# STM32F398xx register map
File version: 1.0
Registers are 32-bit, read-write, reset 0x0 unless marked. A register's access mark holds for its fields unless they carry their own. Offsets are from the block's base; [hi:lo] are bit positions; {n}, {i} and the like mark numbered series.

## OPAMP1 — Operational Amplifier (OPAMP)
Base 0x40010038; alternate view of OPAMP
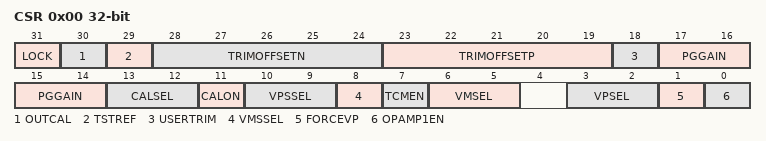
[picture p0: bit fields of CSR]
0x00 CSR — OPAMP control and status register
  [31] LOCK — OPAMP lock
  [30] OUTCAL — OPAMP output status flag
  [29] TSTREF — It enables the switch to put out the internal reference
  [28:24] TRIMOFFSETN — Offset trimming value (NMOS)
  [23:19] TRIMOFFSETP — Offset trimming value (PMOS)
  [18] USERTRIM — User trimming enable
  [17:14] PGGAIN — Gain in PGA mode
  [13:12] CALSEL — Calibration selection
  [11] CALON — Calibration mode enable
  [10:9] VPSSEL — Non inverting input secondary selection
  [8] VMSSEL — Inverting input secondary selection
  [7] TCMEN — Timer-Controlled Mux mode enable
  [6:5] VMSEL — Inverting input selection
  [3:2] VPSEL — Non inverting input selection
  [1] FORCEVP — Connect the internal references to the plus input of the OPAMPX
  [0] OPAMP1EN — OPAMP1 enable

## OPAMP2 — Operational Amplifier (OPAMP)
Base 0x4001003C
Registers as OPAMP1 (with OPAMP1 read as OPAMP2).

## OPAMP3 — Operational Amplifier (OPAMP)
Base 0x40010040
Registers as OPAMP1 (with OPAMP1 read as OPAMP3).

## OPAMP4 — Operational Amplifier (OPAMP)
Base 0x40010044
Registers as OPAMP1 (with OPAMP1 read as OPAMP4).

## EXTI — External Interrupt/Event Controller
Base 0x40010400
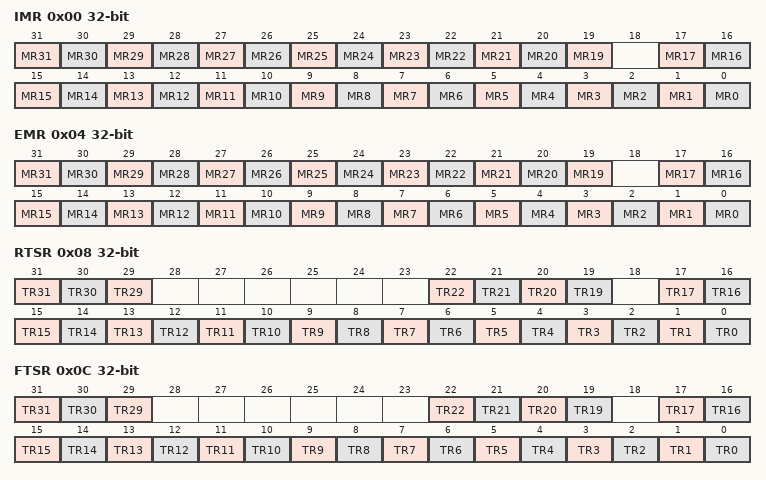
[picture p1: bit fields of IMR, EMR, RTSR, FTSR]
0x00 IMR — EXTI Interrupt mask register
  [n] MR{n} (n=19..31) — Interrupt Mask on line {n}
  [n] MR{n} (n=0..17) — Interrupt Mask on line {n}
0x00 IMR_ALT (alternate view of IMR) — EXTI Interrupt mask register
  [31:0] IM — Interrupt Mask All
0x04 EMR — EXTI Event mask register
  [n] MR{n} (n=19..31) — Event Mask on line {n}
  [n] MR{n} (n=0..17) — Event Mask on line {n}
0x08 RTSR — EXTI Rising trigger selection register
  [31] TR31 — Rising trigger event configuration bit of line 31
  [30] TR30 — Rising trigger event configuration bit of line 30
  [29] TR29 — Rising trigger event configuration bit of line 29
  [n] TR{n} (n=19..22) — Rising trigger event configuration bit of line {n}
  [n] TR{n} (n=0..17) — Rising trigger event configuration bit of line {n}
0x0C FTSR — EXTI Falling trigger selection register
  [31] TR31 — Falling trigger event configuration bit of line 31
  [30] TR30 — Falling trigger event configuration bit of line 30
  [29] TR29 — Falling trigger event configuration bit of line 29
  [n] TR{n} (n=19..22) — Falling trigger event configuration bit of line {n}
  [n] TR{n} (n=0..17) — Falling trigger event configuration bit of line {n}
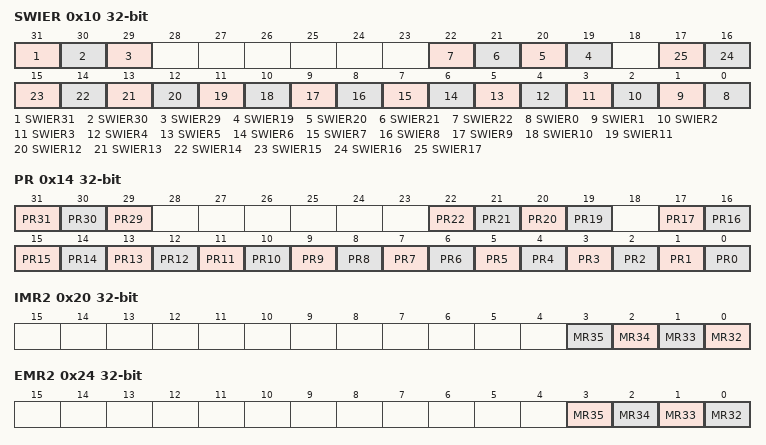
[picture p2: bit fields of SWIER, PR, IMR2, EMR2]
0x10 SWIER — EXTI Software interrupt event register
  [31] SWIER31 — Software Interrupt on line 31
  [30] SWIER30 — Software Interrupt on line 30
  [29] SWIER29 — Software Interrupt on line 29
  [n] SWIER{n} (n=19..22) — Software Interrupt on line {n}
  [n] SWIER{n} (n=0..17) — Software Interrupt on line {n}
0x14 PR — EXTI Pending register
  [31] PR31 — Pending bit for line 31
  [30] PR30 — Pending bit for line 30
  [29] PR29 — Pending bit for line 29
  [n] PR{n} (n=19..22) — Pending bit for line {n}
  [n] PR{n} (n=0..17) — Pending bit for line {n}
0x20 IMR2 — EXTI Interrupt mask register
  [n-32] MR{n} (n=32..35) — Interrupt Mask on line {n}
0x20 IMR2_ALT (alternate view of IMR2) — EXTI Interrupt mask register
  [3:0] IM
0x24 EMR2 — EXTI Event mask register
  [3] MR35 — Event Mask on line 34
  [2] MR34 — Event Mask on line 34
  [1] MR33 — Event Mask on line 33
  [0] MR32 — Event Mask on line 32
0x24 EMR2_ALT (alternate view of EMR2) — EXTI Event mask register
  [3:0] EM
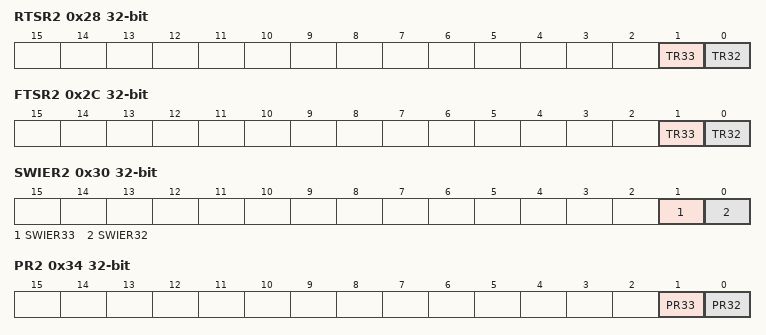
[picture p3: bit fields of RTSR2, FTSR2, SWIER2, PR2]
0x28 RTSR2 — EXTI Rising trigger selection register
  [1] TR33 — Rising trigger event configuration bit of line 33
  [0] TR32 — Rising trigger event configuration bit of line 32
0x2C FTSR2 — EXTI Falling trigger selection register
  [1] TR33 — Falling trigger event configuration bit of line 33
  [0] TR32 — Falling trigger event configuration bit of line 32
0x30 SWIER2 — EXTI Software interrupt event register
  [1] SWIER33 — Software Interrupt on line 33
  [0] SWIER32 — Software Interrupt on line 32
0x34 PR2 — EXTI Pending register
  [1] PR33 — Pending bit for line 33
  [0] PR32 — Pending bit for line 32
